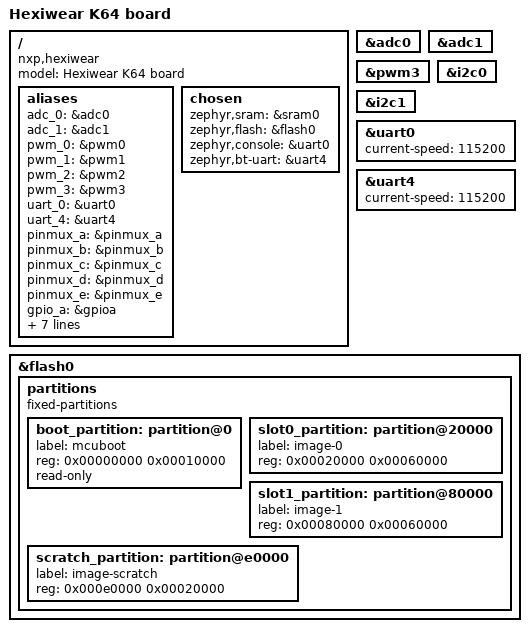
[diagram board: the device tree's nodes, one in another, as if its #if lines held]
/dts-v1/;

#include <nxp/nxp_k6x.dtsi>

/ {
	model = "Hexiwear K64  board";
	compatible = "nxp,hexiwear", "nxp,k64f", "nxp,k6x";

	aliases {
		adc_0 = &adc0;
		adc_1 = &adc1;
		pwm_0 = &pwm0;
		pwm_1 = &pwm1;
		pwm_2 = &pwm2;
		pwm_3 = &pwm3;
		uart_0 = &uart0;
		uart_4 = &uart4;
		pinmux_a = &pinmux_a;
		pinmux_b = &pinmux_b;
		pinmux_c = &pinmux_c;
		pinmux_d = &pinmux_d;
		pinmux_e = &pinmux_e;
		gpio_a = &gpioa;
		gpio_b = &gpiob;
		gpio_c = &gpioc;
		gpio_d = &gpiod;
		gpio_e = &gpioe;
		i2c_0 = &i2c0;
		i2c_1 = &i2c1;
		i2c_2 = &i2c2;
	};

	chosen {
		zephyr,sram = &sram0;
		zephyr,flash = &flash0;
		zephyr,console = &uart0;
#ifdef CONFIG_BT
		zephyr,bt-uart = &uart4;
#endif
	};

};

&adc0 {
	status = "ok";
};

&adc1 {
	status = "ok";
};

&pwm3 {
	status = "ok";
};

&i2c0 {
	status = "ok";
};

&i2c1 {
	status = "ok";
};

&uart0 {
	status = "ok";
	current-speed = <115200>;
};

#ifdef CONFIG_BT
&uart4 {
	status = "ok";
	current-speed = <115200>;
};
#endif

&flash0 {
	/*
	 * If chosen's zephyr,code-partition
	 * is unset, the image will be linked
	 * into the entire flash device.  If
	 * it points to an individual
	 * partition, the code will be linked
	 * to, and restricted to that
	 * partition.
	 */
	partitions {
		compatible = "fixed-partitions";
		#address-cells = <1>;
		#size-cells = <1>;

		boot_partition: partition@0 {
			label = "mcuboot";
			reg = <0x00000000 0x00010000>;
			read-only;
		};

		/*
		 * The flash starting at 0x00010000 and ending at
		 * 0x0001ffff (sectors 16-31) is reserved for use
		 * by the application.
		 */

		slot0_partition: partition@20000 {
			label = "image-0";
			reg = <0x00020000 0x00060000>;
		};
		slot1_partition: partition@80000 {
			label = "image-1";
			reg = <0x00080000 0x00060000>;
		};
		scratch_partition: partition@e0000 {
			label = "image-scratch";
			reg = <0x000e0000 0x00020000>;
		};
	};
};
